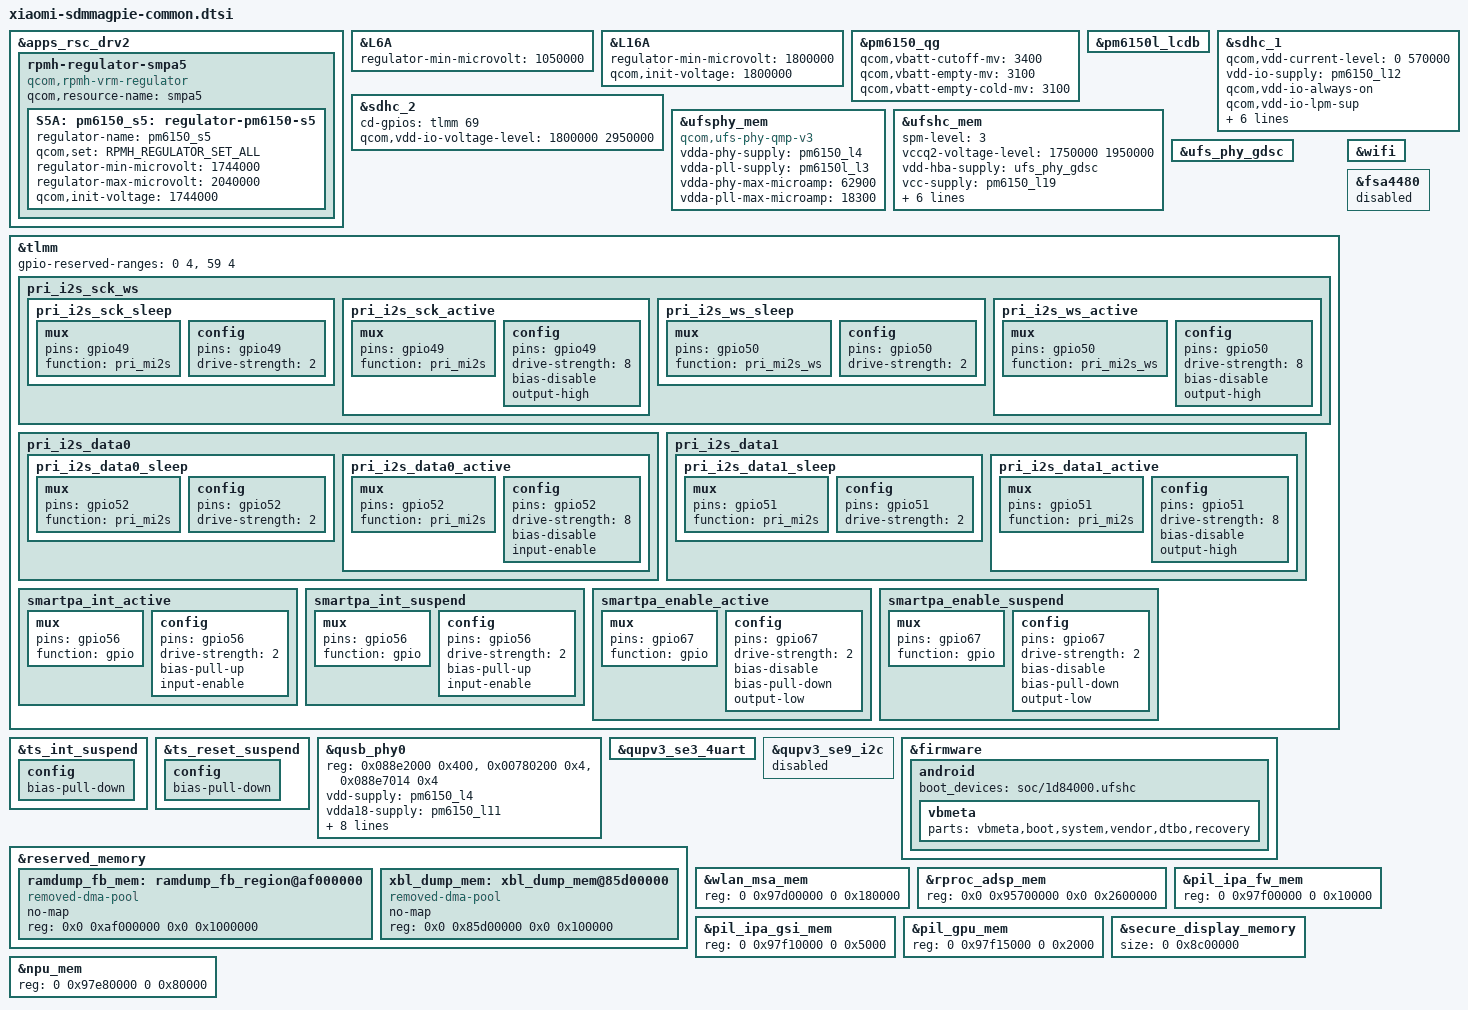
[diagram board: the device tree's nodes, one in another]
/* Generated by dtsplit.py (tools-sdmmagpie) from the 4.14 Xiaomi sdmmagpie common files and the 6.1 violet DT. */

#include "sdmmagpie.dtsi"
#include <dt-bindings/pinctrl/qcom,pmic-gpio.h>

&apps_rsc_drv2 {

	/* FROM-4.14 (dt/414/xiaomi/sdmmagpie-regulator.dtsi): target only, 4.14 bindings, check */
	rpmh-regulator-smpa5 {
		compatible = "qcom,rpmh-vrm-regulator";
		qcom,resource-name = "smpa5";

		/* FROM-4.14 (dt/414/xiaomi/sdmmagpie-regulator.dtsi): target only, 4.14 bindings, check */
		S5A: pm6150_s5: regulator-pm6150-s5 {
			regulator-name = "pm6150_s5";
			qcom,set = <RPMH_REGULATOR_SET_ALL>;
			regulator-min-microvolt = <1744000>;
			regulator-max-microvolt = <2040000>;
			qcom,init-voltage = <1744000>;
		};
	};
};

&L6A {
	regulator-min-microvolt = <1050000>;
};

&L16A {
	regulator-min-microvolt = <1800000>;
	qcom,init-voltage = <1800000>;
};

&pm6150_qg {
	qcom,vbatt-cutoff-mv = <3400>;
	qcom,vbatt-empty-mv = <3100>;
	qcom,vbatt-empty-cold-mv = <3100>;
};

&pm6150l_lcdb {
	/delete-property/ qcom,voltage-step-ramp;
};

&sdhc_1 {
	qcom,vdd-current-level = <0 570000>;
	vdd-io-supply = <&pm6150_l12>;
	qcom,vdd-io-always-on;
	qcom,vdd-io-lpm-sup;
	qcom,vdd-io-voltage-level = <1800000 1800000>;
	qcom,vdd-io-current-level = <0 325000>;
	pinctrl-names = "active", "sleep";
	pinctrl-0 = <&sdc1_clk_on &sdc1_cmd_on &sdc1_data_on &sdc1_rclk_on>;
	pinctrl-1 = <&sdc1_clk_off &sdc1_cmd_off &sdc1_data_off &sdc1_rclk_off>;
};

&sdhc_2 {
	cd-gpios = <&tlmm 69 GPIO_ACTIVE_HIGH>;
	qcom,vdd-io-voltage-level = <1800000 2950000>;
};

&ufsphy_mem {
	status = "okay";
	compatible = "qcom,ufs-phy-qmp-v3";
	vdda-phy-supply = <&pm6150_l4>;
	vdda-pll-supply = <&pm6150l_l3>;
	vdda-phy-max-microamp = <62900>;
	vdda-pll-max-microamp = <18300>;
};

&ufshc_mem {
	spm-level = <3>;
	status = "okay";
	vccq2-voltage-level = <1750000 1950000>;
	vdd-hba-supply = <&ufs_phy_gdsc>;
	vcc-supply = <&pm6150_l19>;
	vcc-voltage-level = <2950000 2960000>;
	vccq2-supply = <&pm6150_l12>;
	vcc-max-microamp = <600000>;
	vccq2-max-microamp = <600000>;
	qcom,vddp-ref-clk-supply = <&pm6150l_l3>;
	qcom,vddp-ref-clk-max-microamp = <100>;
};

&ufs_phy_gdsc {
	status = "okay";
};

&tlmm {
	gpio-reserved-ranges = <0 4>, <59 4>;

	pri_i2s_sck_ws {

		pri_i2s_sck_sleep: pri_i2s_sck_sleep {

			mux {
				pins = "gpio49";
				function = "pri_mi2s";
			};

			config {
				pins = "gpio49";
				drive-strength = <2>;
			};
		};

		pri_i2s_sck_active: pri_i2s_sck_active {

			mux {
				pins = "gpio49";
				function = "pri_mi2s";
			};

			config {
				pins = "gpio49";
				drive-strength = <8>;
				bias-disable;
				output-high;
			};
		};

		pri_i2s_ws_sleep: pri_i2s_ws_sleep {

			mux {
				pins = "gpio50";
				function = "pri_mi2s_ws";
			};

			config {
				pins = "gpio50";
				drive-strength = <2>;
			};
		};

		pri_i2s_ws_active: pri_i2s_ws_active {

			mux {
				pins = "gpio50";
				function = "pri_mi2s_ws";
			};

			config {
				pins = "gpio50";
				drive-strength = <8>;
				bias-disable;
				output-high;
			};
		};
	};

	pri_i2s_data0 {

		pri_i2s_data0_sleep: pri_i2s_data0_sleep {

			mux {
				pins = "gpio52";
				function = "pri_mi2s";
			};

			config {
				pins = "gpio52";
				drive-strength = <2>;
			};
		};

		pri_i2s_data0_active: pri_i2s_data0_active {

			mux {
				pins = "gpio52";
				function = "pri_mi2s";
			};

			config {
				pins = "gpio52";
				drive-strength = <8>;
				bias-disable;
				input-enable;
			};
		};
	};

	pri_i2s_data1 {

		pri_i2s_data1_sleep: pri_i2s_data1_sleep {

			mux {
				pins = "gpio51";
				function = "pri_mi2s";
			};

			config {
				pins = "gpio51";
				drive-strength = <2>;
			};
		};

		pri_i2s_data1_active: pri_i2s_data1_active {

			mux {
				pins = "gpio51";
				function = "pri_mi2s";
			};

			config {
				pins = "gpio51";
				drive-strength = <8>;
				bias-disable;
				output-high;
			};
		};
	};

	smartpa_int_active: smartpa_int_active {

		mux {
			pins = "gpio56";
			function = "gpio";
		};

		config {
			pins = "gpio56";
			drive-strength = <2>;
			bias-pull-up;
			input-enable;
		};
	};

	smartpa_int_suspend: smartpa_int_suspend {

		mux {
			pins = "gpio56";
			function = "gpio";
		};

		config {
			pins = "gpio56";
			drive-strength = <2>;
			bias-pull-up;
			input-enable;
		};
	};

	smartpa_enable_active: smartpa_enable_active {

		mux {
			pins = "gpio67";
			function = "gpio";
		};

		config {
			pins = "gpio67";
			drive-strength = <2>;
			bias-disable;
			bias-pull-down;
			output-low;
		};
	};

	smartpa_enable_suspend: smartpa_enable_suspend {

		mux {
			pins = "gpio67";
			function = "gpio";
		};

		config {
			pins = "gpio67";
			drive-strength = <2>;
			bias-disable;
			bias-pull-down;
			output-low;
		};
	};
};

&ts_int_suspend {

	config {
		bias-pull-down;
	};
};

&ts_reset_suspend {

	config {
		bias-pull-down;
	};
};

&qusb_phy0 {
	/* whole node from 4.14 (dt/414/sdmmagpie-usb.dtsi) */
	reg = <0x088e2000 0x400>, <0x00780200 0x4>, <0x088e7014 0x4>;
	reg-names = "qusb_phy_base", "efuse_addr",
				"refgen_north_bg_reg_addr";
	vdd-supply = <&pm6150_l4>;
	vdda18-supply = <&pm6150_l11>;
	vdda33-supply = <&pm6150_l17>;
	qcom,qusb-phy-init-seq = <0x23 0x210 0x03 0x04 0x7c 0x18c 0x80 0x2c 0x0a 0x184 0x19 0xb4 0x40 0x194 0x1c 0x198 0x21 0x214 0x00 0x220 0x18 0x224 0x16 0x240 0x29 0x244 0xca 0x248 0x02 0x24c 0x03 0x250 0x00 0x23c 0x22 0x210>;
	qcom,qusb-phy-host-init-seq = <0x23 0x210 0x03 0x04 0x7c 0x18c 0x80 0x2c 0x0a 0x184 0x19 0xb4 0x40 0x194 0x20 0x198 0x21 0x214 0x00 0x220 0x18 0x224 0x37 0x240 0x29 0x244 0xca 0x248 0x04 0x24c 0x03 0x250 0x00 0x23c 0x22 0x210>;
	clocks = <&rpmhcc RPMH_CXO_CLK>, <&gcc GCC_USB_PHY_CFG_AHB2PHY_CLK>;
	clock-names = "ref_clk_src", "cfg_ahb_clk";
	resets = <&gcc GCC_QUSB2PHY_PRIM_BCR>;
};

&wifi {
	/delete-property/ vdd-3.3-ch1-supply;
};

&qupv3_se3_4uart {
	status = "ok";
};

&qupv3_se9_i2c {
	status = "disabled";
};

&fsa4480 {
	status = "disabled";
};

&firmware {

	android {
		boot_devices = "soc/1d84000.ufshc";

		vbmeta {
			parts = "vbmeta,boot,system,vendor,dtbo,recovery";
		};
	};
};

&reserved_memory {

	/* FROM-4.14 (dt/414/xiaomi/xiaomi-sdmmagpie-common.dtsi): target only, 4.14 bindings, check */
	ramdump_fb_mem: ramdump_fb_region@af000000 {
		compatible = "removed-dma-pool";
		no-map;
		reg = <0x0 0xaf000000 0x0 0x1000000>;
	};

	/* FROM-4.14 (dt/414/xiaomi/xiaomi-sdmmagpie-common.dtsi): target only, 4.14 bindings, check */
	xbl_dump_mem: xbl_dump_mem@85d00000 {
		compatible = "removed-dma-pool";
		no-map;
		reg = <0x0 0x85d00000 0x0 0x100000>;
	};
};

&wlan_msa_mem {
	reg = <0 0x97d00000 0 0x180000>;
};

&rproc_adsp_mem {
	reg = <0x0 0x95700000 0x0 0x2600000>;
};

&pil_ipa_fw_mem {
	reg = <0 0x97f00000 0 0x10000>;
};

&pil_ipa_gsi_mem {
	reg = <0 0x97f10000 0 0x5000>;
};

&pil_gpu_mem {
	reg = <0 0x97f15000 0 0x2000>;
};

&secure_display_memory {
	size = <0 0x8c00000>;
};

&npu_mem {
	/* FROM-4.14 (dt/414/xiaomi/xiaomi-sdmmagpie-common.dtsi): target only, 4.14 bindings, check */
	reg = <0 0x97e80000 0 0x80000>;
};
